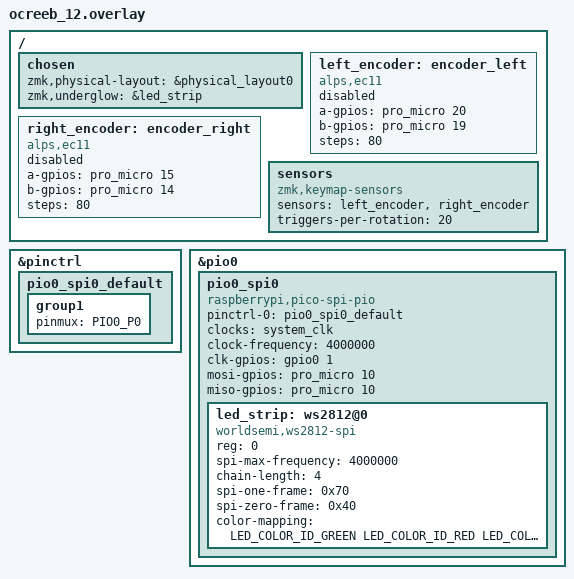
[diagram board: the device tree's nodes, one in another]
// This file was generated from a template. Edit it to match your keyboard.
// See https://zmk.dev/docs/development/hardware-integration/new-shield for more
// instructions.

#include <dt-bindings/zmk/matrix_transform.h>
#include <dt-bindings/led/led.h>

#include "ocreeb_12-layouts.dtsi"

/ {
    chosen {
        zmk,physical-layout = &physical_layout0;
        zmk,underglow = &led_strip;
    };

    // Pin 18 is for encoder push
    left_encoder: encoder_left {
        compatible = "alps,ec11";
        a-gpios = <&pro_micro 20 (GPIO_ACTIVE_HIGH | GPIO_PULL_UP)>;
        b-gpios = <&pro_micro 19 (GPIO_ACTIVE_HIGH | GPIO_PULL_UP)>;
        steps = <80>;
        status = "enabled";
    };

    // D16 for encoder push
    right_encoder: encoder_right {
        compatible = "alps,ec11";
        a-gpios = <&pro_micro 15 (GPIO_ACTIVE_HIGH | GPIO_PULL_UP)>;
        b-gpios = <&pro_micro 14 (GPIO_ACTIVE_HIGH | GPIO_PULL_UP)>;
        steps = <80>;
        status = "enabled";
    };

    sensors: sensors {
        compatible = "zmk,keymap-sensors";
        sensors = <&left_encoder &right_encoder>;
        triggers-per-rotation = <20>;
    };
};

&pinctrl {
    pio0_spi0_default: pio0_spi0_default {
        group1 {
            pinmux = <PIO0_P0>;
        };
    };
};

&pio0 {
    status = "okay";

    pio0_spi0: pio0_spi0 {
        pinctrl-0 = <&pio0_spi0_default>;
        pinctrl-names = "default";

        compatible = "raspberrypi,pico-spi-pio";
        #address-cells = <1>;
        #size-cells = <0>;
        clocks = <&system_clk>;
        clock-frequency = <4000000>;

        clk-gpios = <&gpio0 1 GPIO_ACTIVE_HIGH>;     /* Must be defined. Select a pin that is not used elsewhere. */
        mosi-gpios = <&pro_micro 10 GPIO_ACTIVE_HIGH>; /* Data In pin. */
        miso-gpios = <&pro_micro 10 GPIO_ACTIVE_HIGH>; /* Must be defined. Re-using the DI pin is OK for WS2812. */

        led_strip: ws2812@0 {
            compatible = "worldsemi,ws2812-spi";

            /* SPI */
            reg = <0>; /* ignored, but necessary for SPI bindings */
            spi-max-frequency = <4000000>;

            /* WS2812 */
            chain-length = <4>; /* number of LEDs */
            spi-one-frame = <0x70>;
            spi-zero-frame = <0x40>;
            color-mapping = <LED_COLOR_ID_GREEN
                             LED_COLOR_ID_RED
                             LED_COLOR_ID_BLUE
                             LED_COLOR_ID_WHITE>;
        };
    };
};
